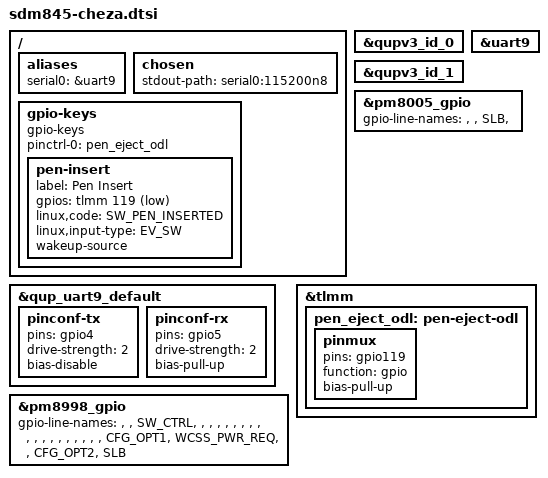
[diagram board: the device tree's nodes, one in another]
// SPDX-License-Identifier: (GPL-2.0+ OR MIT)
/*
 * Google Cheza device tree source (common between revisions)
 *
 * Copyright 2018 Google LLC.
 */

#include <dt-bindings/gpio/gpio.h>
#include <dt-bindings/input/input.h>
#include "sdm845.dtsi"

/* PMICs depend on spmi_bus label and so must come after SoC */
#include "pm8005.dtsi"
#include "pm8998.dtsi"

/ {
	aliases {
		serial0 = &uart9;
	};

	chosen {
		stdout-path = "serial0:115200n8";
	};

	gpio-keys {
		compatible = "gpio-keys";
		pinctrl-names = "default";
		pinctrl-0 = <&pen_eject_odl>;

		pen-insert {
			label = "Pen Insert";
			/* Insert = low, eject = high */
			gpios = <&tlmm 119 GPIO_ACTIVE_LOW>;
			linux,code = <SW_PEN_INSERTED>;
			linux,input-type = <EV_SW>;
			wakeup-source;
		};
	};
};

&qupv3_id_0 {
	status = "okay";
};

&qupv3_id_1 {
	status = "okay";
};

&uart9 {
	status = "okay";
};

/* PINCTRL - additions to nodes defined in sdm845.dtsi */

&qup_uart9_default {
	pinconf-tx {
		pins = "gpio4";
		drive-strength = <2>;
		bias-disable;
	};

	pinconf-rx {
		pins = "gpio5";
		drive-strength = <2>;
		bias-pull-up;
	};
};

/* PINCTRL - board-specific pinctrl */
&pm8005_gpio {
	gpio-line-names = "",
			  "",
			  "SLB",
			  "";
};

&pm8998_gpio {
	gpio-line-names = "",
			  "",
			  "SW_CTRL",
			  "",
			  "",
			  "",
			  "",
			  "",
			  "",
			  "",
			  "",
			  "",
			  "",
			  "",
			  "",
			  "",
			  "",
			  "",
			  "",
			  "",
			  "",
			  "CFG_OPT1",
			  "WCSS_PWR_REQ",
			  "",
			  "CFG_OPT2",
			  "SLB";
};

&tlmm {
	pen_eject_odl: pen-eject-odl {
		pinmux {
			pins = "gpio119";
			function = "gpio";
			bias-pull-up;
		};
	};
};
